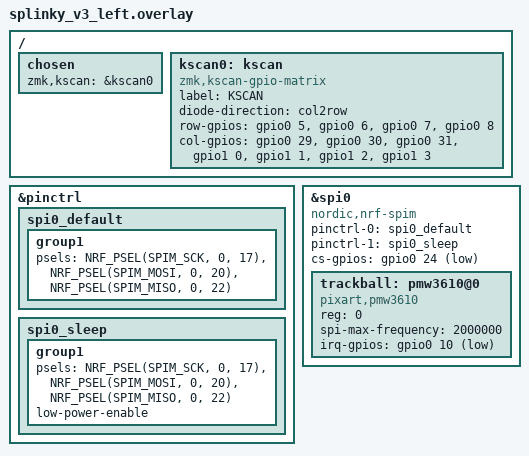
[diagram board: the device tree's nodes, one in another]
/*
 * Copyright (c) 2023 The ZMK Contributors
 *
 * SPDX-License-Identifier: MIT
 */

/ {
    chosen {
        zmk,kscan = &kscan0;
    };

    kscan0: kscan {
        compatible = "zmk,kscan-gpio-matrix";
        label = "KSCAN";

        diode-direction = "col2row";
        row-gpios
            = <&gpio0 5 (GPIO_ACTIVE_HIGH | GPIO_PULL_DOWN)>
            , <&gpio0 6 (GPIO_ACTIVE_HIGH | GPIO_PULL_DOWN)>
            , <&gpio0 7 (GPIO_ACTIVE_HIGH | GPIO_PULL_DOWN)>
            , <&gpio0 8 (GPIO_ACTIVE_HIGH | GPIO_PULL_DOWN)>
            ;
        col-gpios
            = <&gpio0 29 GPIO_ACTIVE_HIGH>
            , <&gpio0 30 GPIO_ACTIVE_HIGH>
            , <&gpio0 31 GPIO_ACTIVE_HIGH>
            , <&gpio1 0 GPIO_ACTIVE_HIGH>
            , <&gpio1 1 GPIO_ACTIVE_HIGH>
            , <&gpio1 2 GPIO_ACTIVE_HIGH>
            , <&gpio1 3 GPIO_ACTIVE_HIGH>
            ;
    };
};

&pinctrl {
    spi0_default: spi0_default {
        group1 {
            psels = <NRF_PSEL(SPIM_SCK, 0, 17)>,
                <NRF_PSEL(SPIM_MOSI, 0, 20)>,
                <NRF_PSEL(SPIM_MISO, 0, 22)>;
        };
    };

    spi0_sleep: spi0_sleep {
        group1 {
            psels = <NRF_PSEL(SPIM_SCK, 0, 17)>,
                <NRF_PSEL(SPIM_MOSI, 0, 20)>,
                <NRF_PSEL(SPIM_MISO, 0, 22)>;
            low-power-enable;
        };
    };
};

&spi0 {
    compatible = "nordic,nrf-spim";
    status = "okay";
    pinctrl-0 = <&spi0_default>;
    pinctrl-1 = <&spi0_sleep>;
    pinctrl-names = "default", "sleep";

    cs-gpios = <&gpio0 24 GPIO_ACTIVE_LOW>;

    trackball: pmw3610@0 {
        status = "okay";
        compatible = "pixart,pmw3610";
        reg = <0>;
        spi-max-frequency = <2000000>;
        irq-gpios = <&gpio0 10 (GPIO_ACTIVE_LOW | GPIO_PULL_UP)>;
    };
};
